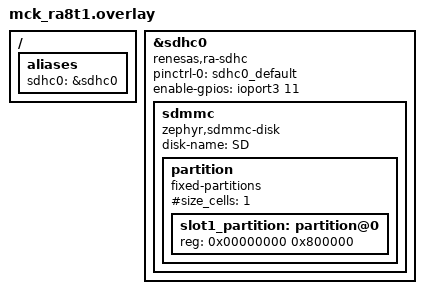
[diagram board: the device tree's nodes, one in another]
/*
 * Copyright (c) 2024 Renesas Electronics Corporation
 * SPDX-License-Identifier: Apache-2.0
 */

/ {
	aliases {
		sdhc0 = &sdhc0;
	};
};

&sdhc0 {
	compatible = "renesas,ra-sdhc";
	pinctrl-0 = <&sdhc0_default>;
	enable-gpios = <&ioport3 11 GPIO_ACTIVE_HIGH>;
	pinctrl-names = "default";
	status = "okay";
	sdmmc {
		compatible = "zephyr,sdmmc-disk";
		disk-name = "SD";
		status = "okay";
		partition {
			compatible = "fixed-partitions";
			#address-cells = <1>;
			#size_cells = <1>;
			slot1_partition: partition@0 {
				reg = <0x00000000 0x800000>;
			};
		};
	};
};
